VERSION ""

NS_ :

BS_:
BU_: Module-253 Module-C02 Module-902 Module-501 Module-401 Module-254 Module-8002
BO_ 595 DestonerModule: 8 Module-253
   SG_ Joy1Down : 1|1@0+ (1,0) [0|1] "" Module-253
   SG_ Joy1Up : 0|1@0+ (1,0) [0|1] "" Module-253
   SG_ Joy1Left : 2|1@0+ (1,0) [0|1] "" Module-253
   SG_ Joy1Right : 3|1@0+ (1,0) [0|1] "" Module-253
   SG_ Joy3Up : 4|1@0+ (1,0) [0|1] "" Module-253
   SG_ Joy3Down : 5|1@0+ (1,0) [0|1] "" Module-253
   SG_ Joy3Left : 6|1@0+ (1,0) [0|1] "" Module-253
   SG_ Joy3Right : 7|1@0+ (1,0) [0|1] "" Module-253
   SG_ Joy1Button : 42|1@0+ (1,0) [0|1] "" Vector__XXX
   SG_ Joy2Button : 40|1@0+ (1,0) [0|1] "" Module-253
   SG_ Joy3Button : 41|1@0+ (1,0) [0|1] "" Module-253
   SG_ Joy2Up : 48|1@0+ (1,0) [0|1] "" Module-253
   SG_ Joy2Down : 49|1@0+ (1,0) [0|1] "" Module-253
   SG_ Joy2Left : 50|1@0+ (1,0) [0|1] "" Module-253
   SG_ Joy2Right : 51|1@0+ (1,0) [0|1] "" Module-253
   SG_ NewModule : 58|1@0+ (1,0) [0|1] "" Module-253
   SG_ OldModule : 56|2@1+ (1,0) [0|1] "" Module-253
   SG_ JOYSTICK_2_X : 8|16@1+ (1,0) [0|1] "" Vector__XXX
   SG_ JOYSTICK_2_Y : 24|16@1+ (1,0) [0|1] "" Vector__XXX

BO_ 2566880258 DestonerModuleC02: 8 Module-C02
   SG_ FlowRange : 56|8@1+ (1,0) [0|1] "" Vector__XXX
   SG_ Flow-w-HMs : 48|8@1+ (1,0) [0|1] "" Vector__XXX

BO_ 2566883586 JoystickOrientation: 8 Module-902
   SG_ JoystickOrientation : 32|1@0+ (1,0) [0|1] "" Vector__XXX
   SG_ SteeringCentre : 0|16@1+ (1,0) [0|1] "" Vector__XXX

BO_ 2365523201 Module-501: 8 Module-501
   SG_ Angle_MV : 0|16@1+ (1,0) [0|1] "" Vector__XXX
   SG_ SteeringAutoCentre : 57|1@0+ (1,0) [0|1] "" Module-253

BO_ 2365527041 Module-401: 8 Module-401
   SG_ HMS-State : 0|1@0+ (1,0) [0|1] "" Vector__XXX

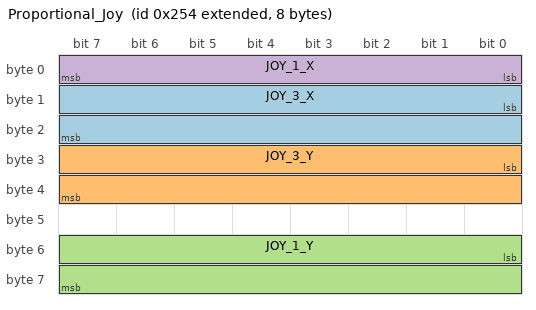
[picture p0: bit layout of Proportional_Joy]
BO_ 2147484244 Proportional_Joy: 8 Module-254
   SG_ JOY_3_X : 8|16@1+ (1,0) [0|1] "" Vector__XXX
   SG_ JOY_3_Y : 24|16@1+ (1,0) [0|1] "" Vector__XXX
   SG_ JOY_1_Y : 48|16@1+ (1,0) [0|1] "" Vector__XXX
   SG_ JOY_1_X : 0|8@1+ (1,0) [0|1] "" Vector__XXX

BO_ 2566881282 TransportLock: 8 Module-8002
   SG_ TransportLock : 52|1@0+ (1,0) [0|1] "" Module-253

BA_DEF_ BO_ "GenMsgBackgroundColor" STRING ;
BA_DEF_ BO_ "GenMsgForegroundColor" STRING ;
BA_DEF_ BO_ "filterlabeling" INT 0 0;
BA_DEF_ BO_ "filterlabeling" INT 0 0;
BA_DEF_ BO_ "filterlabeling" INT 0 0;
BA_DEF_DEF_ "GenMsgBackgroundColor" "#2d2d2d";
BA_DEF_DEF_ "GenMsgForegroundColor" "#ffffff";
BA_DEF_DEF_ "filterlabeling" 1;
BA_DEF_DEF_ "filterlabeling" 1;
VAL_ 595 Joy1Down 0 "--" 1 "Engaged";
VAL_ 595 Joy1Up 0 "--" 1 "Engaged";
VAL_ 595 Joy1Left 0 "--" 1 "Engaged";
VAL_ 595 Joy1Right 0 "--" 1 "Engaged";
VAL_ 595 Joy3Up 0 "--" 1 "Engaged";
VAL_ 595 Joy3Down 0 "--" 1 "Engaged";
VAL_ 595 Joy3Left 0 "--" 1 "Engaged";
VAL_ 595 Joy3Right 0 "--" 1 "Engaged";
VAL_ 595 Joy1Button 0 "--" 1 "Engaged";
VAL_ 595 Joy2Button 0 "--" 1 "Engaged";
VAL_ 595 Joy3Button 0 "--" 1 "Engaged";
VAL_ 595 Joy2Up 0 "--" 1 "Engaged";
VAL_ 595 Joy2Down 0 "--" 1 "Engaged";
VAL_ 595 Joy2Left 0 "--" 1 "Engaged";
VAL_ 595 Joy2Right 0 "--" 1 "Engaged";
VAL_ 595 NewModule 0 "False" 1 "True";
VAL_ 595 OldModule 0 "False" 3 "True" 1 "False" 2 "False";
VAL_ 2566883586 JoystickOrientation 0 "Left-Right" 1 "Up-Down";
VAL_ 2365523201 SteeringAutoCentre 0 "OFF" 1 "ON";
VAL_ 2365527041 HMS-State 0 "Off" 1 "On";
VAL_ 2566881282 TransportLock 0 "OFF" 1 "ON";
